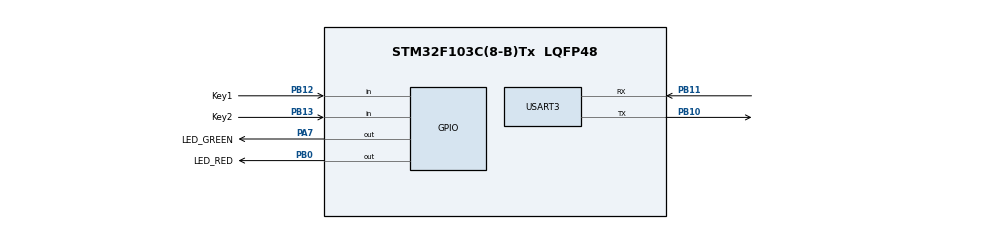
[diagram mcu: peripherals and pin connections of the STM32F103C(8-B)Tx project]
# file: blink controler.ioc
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Mcu.Family=STM32F1
Mcu.Name=STM32F103C(8-B)Tx
Mcu.Package=LQFP48
NVIC.PriorityGroup=NVIC_PRIORITYGROUP_4
PA7.GPIO_Label=LED_GREEN
PA7.Signal=GPIO_Output
PB0.GPIO_Label=LED_RED
PB0.Signal=GPIO_Output
PB10.Mode=Asynchronous
PB10.Signal=USART3_TX
PB11.Mode=Asynchronous
PB11.Signal=USART3_RX
PB12.GPIO_Label=Key1
PB12.Signal=GPIO_Input
PB13.GPIO_Label=Key2
PB13.GPIO_PuPd=GPIO_PULLUP
PB13.Signal=GPIO_Input
ProjectManager.HeapSize=0x200
ProjectManager.StackSize=0x400
ProjectManager.TargetToolchain=STM32CubeIDE
RCC.APB1Freq_Value=8000000
RCC.APB2Freq_Value=8000000
USART3.VirtualMode=VM_ASYNC
VP_SYS_VS_ND.Mode=No_Debug
board=custom

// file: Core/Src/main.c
/* USER CODE BEGIN Header */
/**
 ******************************************************************************
 * @file           : main.c
 * @brief          : Main program body
 ******************************************************************************
 * @attention
 *
 * Copyright (c) 2022 STMicroelectronics.
 * All rights reserved.
 *
 * This software is licensed under terms that can be found in the LICENSE file
 * in the root directory of this software component.
 * If no LICENSE file comes with this software, it is provided AS-IS.
 *
 ******************************************************************************
 */
/* USER CODE END Header */
#include "main.h"

UART_HandleTypeDef huart3;

void SystemClock_Config(void);
static void MX_GPIO_Init(void);
static void MX_USART3_UART_Init(void);

int main(void)
{

  /* MCU Configuration--------------------------------------------------------*/

  /* Reset of all peripherals, Initializes the Flash interface and the Systick. */
  HAL_Init();

  /* Configure the system clock */
  SystemClock_Config();

  /* Initialize all configured peripherals */
  MX_GPIO_Init();
  MX_USART3_UART_Init();

  /* Infinite loop */
  /* USER CODE BEGIN WHILE */
	while (1) {
		// 如果KEY1按下，就点亮绿灯
		if(HAL_GPIO_ReadPin(KEY1_GPIO_Port, KEY1_Pin) == GPIO_PIN_RESET){
			HAL_GPIO_WritePin(GREEN_GPIO_Port, GREEN_Pin, GPIO_PIN_SET);
		}
		// 否则，就熄灭绿灯
		else{
			HAL_GPIO_WritePin(GREEN_GPIO_Port, GREEN_Pin, GPIO_PIN_RESET);
		}

		// KEY2消抖
		if (!HAL_GPIO_ReadPin(KEY2_GPIO_Port, KEY2_Pin)) {
			// 如果检测到KEY2低电平，先延时等待50ms
			HAL_Delay(50);
			// 再判断KEY2是否还处于低电平
			if (!HAL_GPIO_ReadPin(KEY2_GPIO_Port, KEY2_Pin)) {
				// 确认不是抖动，蓝灯亮灭翻转
				HAL_GPIO_TogglePin(BLUE_GPIO_Port, BLUE_Pin);
				// 等待KEY2松开，才能开始下一次检测
				while (!HAL_GPIO_ReadPin(KEY2_GPIO_Port, KEY2_Pin)) {
				}

//		HAL_Delay(50);
    /* USER CODE END WHILE */

	}
}

void SystemClock_Config(void)
{
  RCC_OscInitTypeDef RCC_OscInitStruct = {0};
  RCC_ClkInitTypeDef RCC_ClkInitStruct = {0};

  /** Initializes the RCC Oscillators according to the specified parameters
  * in the RCC_OscInitTypeDef structure.
  */
  RCC_OscInitStruct.OscillatorType = RCC_OSCILLATORTYPE_HSI;
  RCC_OscInitStruct.HSIState = RCC_HSI_ON;
  RCC_OscInitStruct.HSICalibrationValue = RCC_HSICALIBRATION_DEFAULT;
  RCC_OscInitStruct.PLL.PLLState = RCC_PLL_NONE;
  if (HAL_RCC_OscConfig(&RCC_OscInitStruct) != HAL_OK)
  {
    Error_Handler();
  }

  /** Initializes the CPU, AHB and APB buses clocks
  */
  RCC_ClkInitStruct.ClockType = RCC_CLOCKTYPE_HCLK|RCC_CLOCKTYPE_SYSCLK
                              |RCC_CLOCKTYPE_PCLK1|RCC_CLOCKTYPE_PCLK2;
  RCC_ClkInitStruct.SYSCLKSource = RCC_SYSCLKSOURCE_HSI;
  RCC_ClkInitStruct.AHBCLKDivider = RCC_SYSCLK_DIV1;
  RCC_ClkInitStruct.APB1CLKDivider = RCC_HCLK_DIV1;
  RCC_ClkInitStruct.APB2CLKDivider = RCC_HCLK_DIV1;

  if (HAL_RCC_ClockConfig(&RCC_ClkInitStruct, FLASH_LATENCY_0) != HAL_OK)
  {
    Error_Handler();
  }
}

static void MX_USART3_UART_Init(void)
{

  huart3.Instance = USART3;
  huart3.Init.BaudRate = 115200;
  huart3.Init.WordLength = UART_WORDLENGTH_8B;
  huart3.Init.StopBits = UART_STOPBITS_1;
  huart3.Init.Parity = UART_PARITY_NONE;
  huart3.Init.Mode = UART_MODE_TX_RX;
  huart3.Init.HwFlowCtl = UART_HWCONTROL_NONE;
  huart3.Init.OverSampling = UART_OVERSAMPLING_16;
  if (HAL_UART_Init(&huart3) != HAL_OK)
  {
    Error_Handler();
  }

}

static void MX_GPIO_Init(void)
{
  GPIO_InitTypeDef GPIO_InitStruct = {0};

  /* GPIO Ports Clock Enable */
  __HAL_RCC_GPIOA_CLK_ENABLE();
  __HAL_RCC_GPIOB_CLK_ENABLE();

  /*Configure GPIO pin Output Level */
  HAL_GPIO_WritePin(LED_GREEN_GPIO_Port, LED_GREEN_Pin, GPIO_PIN_RESET);

  /*Configure GPIO pin Output Level */
  HAL_GPIO_WritePin(LED_RED_GPIO_Port, LED_RED_Pin, GPIO_PIN_RESET);

  /*Configure GPIO pin : LED_GREEN_Pin */
  GPIO_InitStruct.Pin = LED_GREEN_Pin;
  GPIO_InitStruct.Mode = GPIO_MODE_OUTPUT_PP;
  GPIO_InitStruct.Pull = GPIO_NOPULL;
  GPIO_InitStruct.Speed = GPIO_SPEED_FREQ_LOW;
  HAL_GPIO_Init(LED_GREEN_GPIO_Port, &GPIO_InitStruct);

  /*Configure GPIO pin : LED_RED_Pin */
  GPIO_InitStruct.Pin = LED_RED_Pin;
  GPIO_InitStruct.Mode = GPIO_MODE_OUTPUT_PP;
  GPIO_InitStruct.Pull = GPIO_NOPULL;
  GPIO_InitStruct.Speed = GPIO_SPEED_FREQ_LOW;
  HAL_GPIO_Init(LED_RED_GPIO_Port, &GPIO_InitStruct);

  /*Configure GPIO pin : Key1_Pin */
  GPIO_InitStruct.Pin = Key1_Pin;
  GPIO_InitStruct.Mode = GPIO_MODE_INPUT;
  GPIO_InitStruct.Pull = GPIO_NOPULL;
  HAL_GPIO_Init(Key1_GPIO_Port, &GPIO_InitStruct);

  /*Configure GPIO pin : Key2_Pin */
  GPIO_InitStruct.Pin = Key2_Pin;
  GPIO_InitStruct.Mode = GPIO_MODE_INPUT;
  GPIO_InitStruct.Pull = GPIO_PULLUP;
  HAL_GPIO_Init(Key2_GPIO_Port, &GPIO_InitStruct);

}

void Error_Handler(void)
{
	__disable_irq();
	while (1) {
	}
}
